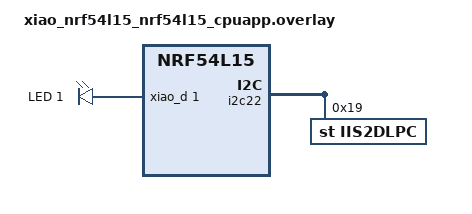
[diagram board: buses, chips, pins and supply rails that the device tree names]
/*
 * Copyright (c) 2024 EdgeImpulse Inc.
 *
 * Licensed under the Apache License, Version 2.0 (the "License");
 * you may not use this file except in compliance with the License.
 * You may obtain a copy of the License at
 * http://www.apache.org/licenses/LICENSE-2.0
 *
 * Unless required by applicable law or agreed to in writing,
 * software distributed under the License is distributed on an "AS
 * IS" BASIS, WITHOUT WARRANTIES OR CONDITIONS OF ANY KIND, either
 * express or implied. See the License for the specific language
 * governing permissions and limitations under the License.
 *
 * SPDX-License-Identifier: Apache-2.0
 */

/ {
    leds{
        led1: led_1 {
			gpios = <&xiao_d 1 GPIO_ACTIVE_HIGH>;
			label = "LED 1";
		};
    };
    
    aliases {
        led1 = &led1;
    };
};


&i2c22 {
    status = "okay";
    pinctrl-0 = <&i2c22_default>;
    pinctrl-1 = <&i2c22_sleep>;
    pinctrl-names = "default", "sleep";
    iis2dlpc: iis2dlpc@19{
        compatible = "st,iis2dlpc";
        status = "okay";
        reg = < 0x19 >;
    };
};
